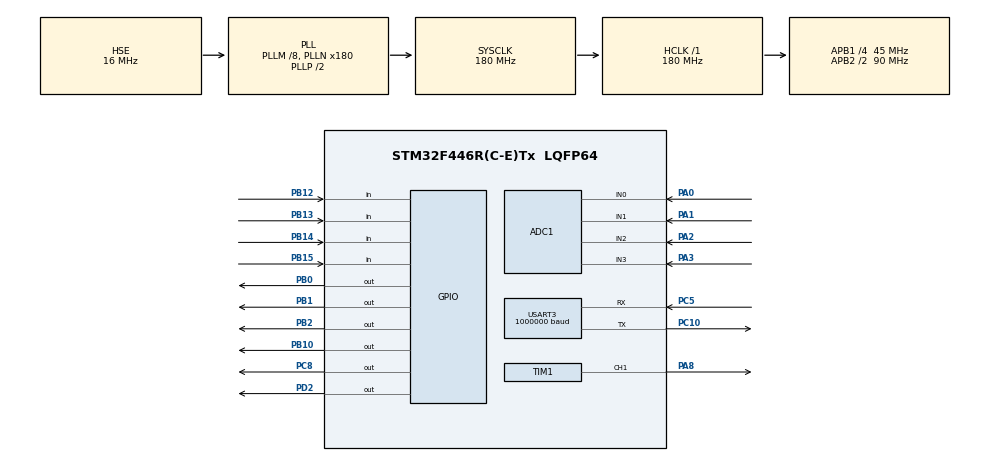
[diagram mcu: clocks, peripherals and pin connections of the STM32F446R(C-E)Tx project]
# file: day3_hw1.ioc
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ADC1.Channel-0\#ChannelRegularConversion=ADC_CHANNEL_0
ADC1.Channel-1\#ChannelRegularConversion=ADC_CHANNEL_1
ADC1.Channel-2\#ChannelRegularConversion=ADC_CHANNEL_2
ADC1.Channel-3\#ChannelRegularConversion=ADC_CHANNEL_3
ADC1.DMAContinuousRequests=ENABLE
ADC1.ExternalTrigConv=ADC_EXTERNALTRIGCONV_T8_TRGO
ADC1.NbrOfConversion=4
ADC1.NbrOfConversionFlag=1
ADC1.Rank-0\#ChannelRegularConversion=1
ADC1.Rank-1\#ChannelRegularConversion=2
ADC1.Rank-2\#ChannelRegularConversion=3
ADC1.Rank-3\#ChannelRegularConversion=4
ADC1.SamplingTime-0\#ChannelRegularConversion=ADC_SAMPLETIME_15CYCLES
ADC1.SamplingTime-1\#ChannelRegularConversion=ADC_SAMPLETIME_15CYCLES
ADC1.SamplingTime-2\#ChannelRegularConversion=ADC_SAMPLETIME_15CYCLES
ADC1.SamplingTime-3\#ChannelRegularConversion=ADC_SAMPLETIME_15CYCLES
ADC1.ScanConvMode=ENABLE
ADC1.master=1
Dma.ADC1.0.Direction=DMA_PERIPH_TO_MEMORY
Dma.ADC1.0.FIFOMode=DMA_FIFOMODE_DISABLE
Dma.ADC1.0.Instance=DMA2_Stream0
Dma.ADC1.0.MemDataAlignment=DMA_MDATAALIGN_WORD
Dma.ADC1.0.MemInc=DMA_MINC_ENABLE
Dma.ADC1.0.Mode=DMA_CIRCULAR
Dma.ADC1.0.PeriphDataAlignment=DMA_PDATAALIGN_WORD
Dma.ADC1.0.PeriphInc=DMA_PINC_DISABLE
Dma.ADC1.0.Priority=DMA_PRIORITY_LOW
Dma.Request0=ADC1
Dma.Request1=USART3_RX
Dma.USART3_RX.1.Direction=DMA_PERIPH_TO_MEMORY
Dma.USART3_RX.1.FIFOMode=DMA_FIFOMODE_DISABLE
Dma.USART3_RX.1.Instance=DMA1_Stream1
Dma.USART3_RX.1.MemDataAlignment=DMA_MDATAALIGN_BYTE
Dma.USART3_RX.1.MemInc=DMA_MINC_ENABLE
Dma.USART3_RX.1.Mode=DMA_CIRCULAR
Dma.USART3_RX.1.PeriphDataAlignment=DMA_PDATAALIGN_BYTE
Dma.USART3_RX.1.PeriphInc=DMA_PINC_DISABLE
Dma.USART3_RX.1.Priority=DMA_PRIORITY_LOW
Mcu.Family=STM32F4
Mcu.Name=STM32F446R(C-E)Tx
Mcu.Package=LQFP64
NVIC.ADC_IRQn=true\:0\:0\:false\:false\:true\:true\:true\:true
NVIC.DMA1_Stream1_IRQn=true\:0\:0\:false\:false\:true\:false\:true\:true
NVIC.DMA2_Stream0_IRQn=true\:0\:0\:false\:false\:true\:false\:true\:true
NVIC.PriorityGroup=NVIC_PRIORITYGROUP_4
NVIC.TIM1_BRK_TIM9_IRQn=true\:0\:0\:false\:false\:true\:true\:true\:true
NVIC.TIM1_CC_IRQn=true\:0\:0\:false\:false\:true\:true\:true\:true
NVIC.TIM1_TRG_COM_TIM11_IRQn=true\:0\:0\:false\:false\:true\:true\:true\:true
NVIC.TIM1_UP_TIM10_IRQn=true\:0\:0\:false\:false\:true\:true\:true\:true
NVIC.TIM6_DAC_IRQn=true\:0\:0\:false\:false\:true\:true\:true\:true
NVIC.TIM8_BRK_TIM12_IRQn=true\:0\:0\:false\:false\:true\:true\:true\:true
NVIC.TIM8_CC_IRQn=true\:0\:0\:false\:false\:true\:true\:true\:true
NVIC.TIM8_TRG_COM_TIM14_IRQn=true\:0\:0\:false\:false\:true\:true\:true\:true
NVIC.TIM8_UP_TIM13_IRQn=true\:0\:0\:false\:false\:true\:true\:true\:true
NVIC.USART3_IRQn=true\:0\:0\:false\:false\:true\:true\:true\:true
PA0-WKUP.Signal=ADCx_IN0
PA1.Signal=ADCx_IN1
PA13.Mode=Serial_Wire
PA13.Signal=SYS_JTMS-SWDIO
PA14.Mode=Serial_Wire
PA14.Signal=SYS_JTCK-SWCLK
PA2.Signal=ADCx_IN2
PA3.Signal=ADCx_IN3
PA8.Signal=S_TIM1_CH1
PB0.Signal=GPIO_Output
PB1.Signal=GPIO_Output
PB10.Signal=GPIO_Output
PB12.GPIO_PuPd=GPIO_PULLDOWN
PB12.Signal=GPIO_Input
PB13.GPIO_PuPd=GPIO_PULLDOWN
PB13.Signal=GPIO_Input
PB14.GPIO_PuPd=GPIO_PULLDOWN
PB14.Signal=GPIO_Input
PB15.GPIO_PuPd=GPIO_PULLDOWN
PB15.Signal=GPIO_Input
PB2.Signal=GPIO_Output
PC10.Mode=Asynchronous
PC10.Signal=USART3_TX
PC5.Mode=Asynchronous
PC5.Signal=USART3_RX
PC8.Signal=GPIO_Output
PD2.Signal=GPIO_Output
PH0-OSC_IN.Mode=HSE-External-Oscillator
PH0-OSC_IN.Signal=RCC_OSC_IN
PH1-OSC_OUT.Mode=HSE-External-Oscillator
PH1-OSC_OUT.Signal=RCC_OSC_OUT
ProjectManager.HeapSize=0x200
ProjectManager.StackSize=0x400
ProjectManager.TargetToolchain=STM32CubeIDE
RCC.AHBFreq_Value=180000000
RCC.APB1CLKDivider=RCC_HCLK_DIV4
RCC.APB1Freq_Value=45000000
RCC.APB1TimFreq_Value=90000000
RCC.APB2CLKDivider=RCC_HCLK_DIV2
RCC.APB2Freq_Value=90000000
RCC.APB2TimFreq_Value=180000000
RCC.CortexFreq_Value=180000000
RCC.HCLKFreq_Value=180000000
RCC.HSE_VALUE=16000000
RCC.PLLM=8
RCC.PLLN=180
RCC.PLLSourceVirtual=RCC_PLLSOURCE_HSE
RCC.SYSCLKFreq_VALUE=180000000
RCC.SYSCLKSource=RCC_SYSCLKSOURCE_PLLCLK
RCC.USBFreq_Value=180000000
RCC.VCOOutputFreq_Value=360000000
SH.ADCx_IN0.0=ADC1_IN0,IN0
SH.ADCx_IN1.0=ADC1_IN1,IN1
SH.ADCx_IN2.0=ADC1_IN2,IN2
SH.ADCx_IN3.0=ADC1_IN3,IN3
SH.S_TIM1_CH1.0=TIM1_CH1,PWM Generation1 CH1
TIM1.Channel-PWM\ Generation1\ CH1=TIM_CHANNEL_1
TIM1.Period=500-1
TIM1.Prescaler=18-1
TIM6.Period=100-1
TIM6.Prescaler=90-1
TIM8.Period=500-1
TIM8.Prescaler=18-1
USART3.BaudRate=1000000
USART3.VirtualMode=VM_ASYNC
VP_TIM6_VS_ClockSourceINT.Mode=Enable_Timer
board=custom

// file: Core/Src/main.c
/* USER CODE BEGIN Header */
/**
  ******************************************************************************
  * @file           : main.c
  * @brief          : Main program body
  ******************************************************************************
  * @attention
  *
  * Copyright (c) 2026 STMicroelectronics.
  * All rights reserved.
  *
  * This software is licensed under terms that can be found in the LICENSE file
  * in the root directory of this software component.
  * If no LICENSE file comes with this software, it is provided AS-IS.
  *
  ******************************************************************************
  */
/* USER CODE END Header */
#include "main.h"

ADC_HandleTypeDef hadc1;
DMA_HandleTypeDef hdma_adc1;

TIM_HandleTypeDef htim1;
TIM_HandleTypeDef htim6;
TIM_HandleTypeDef htim8;

void SystemClock_Config(void);
static void MX_GPIO_Init(void);
static void MX_DMA_Init(void);
static void MX_ADC1_Init(void);
static void MX_TIM1_Init(void);
static void MX_TIM8_Init(void);
static void MX_TIM6_Init(void);
static void MX_USART3_UART_Init(void);

int main(void)
{

  /* MCU Configuration--------------------------------------------------------*/

  /* Reset of all peripherals, Initializes the Flash interface and the Systick. */
  HAL_Init();

  /* Configure the system clock */
  SystemClock_Config();

  /* Initialize all configured peripherals */
  MX_GPIO_Init();
  MX_DMA_Init();
  MX_ADC1_Init();
  MX_TIM1_Init();
  MX_TIM8_Init();
  MX_TIM6_Init();
  MX_USART3_UART_Init();
  /* USER CODE BEGIN 2 */
  HAL_GPIO_WritePin(GPIOC, GPIO_PIN_8, GPIO_PIN_SET);  // Motor_Direction_R: 정방향 고정
  HAL_TIM_PWM_Start(&htim1, TIM_CHANNEL_1);
  TIM1->CCR1 = 0;   // 초기 상태: 정지

  /* USER CODE END 2 */

  /* Infinite loop */
  while (1)
  {

    /* USER CODE BEGIN 3 */
	  if(HAL_GPIO_ReadPin(GPIOB, GPIO_PIN_12) == GPIO_PIN_SET) {
	 	  TIM1->CCR1 = 0;
	  }
	  else if(HAL_GPIO_ReadPin(GPIOB, GPIO_PIN_13) == GPIO_PIN_SET) {
	 	  TIM1->CCR1 = 150;
	  }
	  else if(HAL_GPIO_ReadPin(GPIOB, GPIO_PIN_14) == GPIO_PIN_SET) {
	       TIM1->CCR1 = 250;
	  }
	  else if(HAL_GPIO_ReadPin(GPIOB, GPIO_PIN_15) == GPIO_PIN_SET) {
	   	  TIM1->CCR1 = 350;
	  }
	  else {
		  TIM1->CCR1 = 0;   // 아무 스위치도 안 올렸을 때 정지
	  }
  }
  /* USER CODE END 3 */
}

void SystemClock_Config(void)
{
  RCC_OscInitTypeDef RCC_OscInitStruct = {0};
  RCC_ClkInitTypeDef RCC_ClkInitStruct = {0};

  /** Configure the main internal regulator output voltage
  */
  __HAL_RCC_PWR_CLK_ENABLE();
  __HAL_PWR_VOLTAGESCALING_CONFIG(PWR_REGULATOR_VOLTAGE_SCALE1);

  /** Initializes the RCC Oscillators according to the specified parameters
  * in the RCC_OscInitTypeDef structure.
  */
  RCC_OscInitStruct.OscillatorType = RCC_OSCILLATORTYPE_HSE;
  RCC_OscInitStruct.HSEState = RCC_HSE_ON;
  RCC_OscInitStruct.PLL.PLLState = RCC_PLL_ON;
  RCC_OscInitStruct.PLL.PLLSource = RCC_PLLSOURCE_HSE;
  RCC_OscInitStruct.PLL.PLLM = 8;
  RCC_OscInitStruct.PLL.PLLN = 180;
  RCC_OscInitStruct.PLL.PLLP = RCC_PLLP_DIV2;
  RCC_OscInitStruct.PLL.PLLQ = 2;
  RCC_OscInitStruct.PLL.PLLR = 2;
  if (HAL_RCC_OscConfig(&RCC_OscInitStruct) != HAL_OK)
  {
    Error_Handler();
  }

  /** Activate the Over-Drive mode
  */
  if (HAL_PWREx_EnableOverDrive() != HAL_OK)
  {
    Error_Handler();
  }

  /** Initializes the CPU, AHB and APB buses clocks
  */
  RCC_ClkInitStruct.ClockType = RCC_CLOCKTYPE_HCLK|RCC_CLOCKTYPE_SYSCLK
                              |RCC_CLOCKTYPE_PCLK1|RCC_CLOCKTYPE_PCLK2;
  RCC_ClkInitStruct.SYSCLKSource = RCC_SYSCLKSOURCE_PLLCLK;
  RCC_ClkInitStruct.AHBCLKDivider = RCC_SYSCLK_DIV1;
  RCC_ClkInitStruct.APB1CLKDivider = RCC_HCLK_DIV4;
  RCC_ClkInitStruct.APB2CLKDivider = RCC_HCLK_DIV2;

  if (HAL_RCC_ClockConfig(&RCC_ClkInitStruct, FLASH_LATENCY_5) != HAL_OK)
  {
    Error_Handler();
  }
}

static void MX_ADC1_Init(void)
{

  ADC_ChannelConfTypeDef sConfig = {0};

  /** Configure the global features of the ADC (Clock, Resolution, Data Alignment and number of conversion)
  */
  hadc1.Instance = ADC1;
  hadc1.Init.ClockPrescaler = ADC_CLOCK_SYNC_PCLK_DIV4;
  hadc1.Init.Resolution = ADC_RESOLUTION_12B;
  hadc1.Init.ScanConvMode = ENABLE;
  hadc1.Init.ContinuousConvMode = DISABLE;
  hadc1.Init.DiscontinuousConvMode = DISABLE;
  hadc1.Init.ExternalTrigConvEdge = ADC_EXTERNALTRIGCONVEDGE_RISING;
  hadc1.Init.ExternalTrigConv = ADC_EXTERNALTRIGCONV_T8_TRGO;
  hadc1.Init.DataAlign = ADC_DATAALIGN_RIGHT;
  hadc1.Init.NbrOfConversion = 4;
  hadc1.Init.DMAContinuousRequests = ENABLE;
  hadc1.Init.EOCSelection = ADC_EOC_SINGLE_CONV;
  if (HAL_ADC_Init(&hadc1) != HAL_OK)
  {
    Error_Handler();
  }

  /** Configure for the selected ADC regular channel its corresponding rank in the sequencer and its sample time.
  */
  sConfig.Channel = ADC_CHANNEL_0;
  sConfig.Rank = 1;
  sConfig.SamplingTime = ADC_SAMPLETIME_15CYCLES;
  if (HAL_ADC_ConfigChannel(&hadc1, &sConfig) != HAL_OK)
  {
    Error_Handler();
  }

  /** Configure for the selected ADC regular channel its corresponding rank in the sequencer and its sample time.
  */
  sConfig.Channel = ADC_CHANNEL_1;
  sConfig.Rank = 2;
  if (HAL_ADC_ConfigChannel(&hadc1, &sConfig) != HAL_OK)
  {
    Error_Handler();
  }

  /** Configure for the selected ADC regular channel its corresponding rank in the sequencer and its sample time.
  */
  sConfig.Channel = ADC_CHANNEL_2;
  sConfig.Rank = 3;
  if (HAL_ADC_ConfigChannel(&hadc1, &sConfig) != HAL_OK)
  {
    Error_Handler();
  }

  /** Configure for the selected ADC regular channel its corresponding rank in the sequencer and its sample time.
  */
  sConfig.Channel = ADC_CHANNEL_3;
  sConfig.Rank = 4;
  if (HAL_ADC_ConfigChannel(&hadc1, &sConfig) != HAL_OK)
  {
    Error_Handler();
  }

}

static void MX_TIM6_Init(void)
{

  TIM_MasterConfigTypeDef sMasterConfig = {0};

  htim6.Instance = TIM6;
  htim6.Init.Prescaler = 90-1;
  htim6.Init.CounterMode = TIM_COUNTERMODE_UP;
  htim6.Init.Period = 100-1;
  htim6.Init.AutoReloadPreload = TIM_AUTORELOAD_PRELOAD_DISABLE;
  if (HAL_TIM_Base_Init(&htim6) != HAL_OK)
  {
    Error_Handler();
  }
  sMasterConfig.MasterOutputTrigger = TIM_TRGO_RESET;
  sMasterConfig.MasterSlaveMode = TIM_MASTERSLAVEMODE_DISABLE;
  if (HAL_TIMEx_MasterConfigSynchronization(&htim6, &sMasterConfig) != HAL_OK)
  {
    Error_Handler();
  }

}

static void MX_TIM1_Init(void)
{

  TIM_MasterConfigTypeDef sMasterConfig = {0};
  TIM_OC_InitTypeDef sConfigOC = {0};
  TIM_BreakDeadTimeConfigTypeDef sBreakDeadTimeConfig = {0};

  htim1.Instance = TIM1;
  htim1.Init.Prescaler = 18-1;
  htim1.Init.CounterMode = TIM_COUNTERMODE_UP;
  htim1.Init.Period = 500-1;
  htim1.Init.ClockDivision = TIM_CLOCKDIVISION_DIV1;
  htim1.Init.RepetitionCounter = 0;
  htim1.Init.AutoReloadPreload = TIM_AUTORELOAD_PRELOAD_DISABLE;
  if (HAL_TIM_PWM_Init(&htim1) != HAL_OK)
  {
    Error_Handler();
  }
  sMasterConfig.MasterOutputTrigger = TIM_TRGO_RESET;
  sMasterConfig.MasterSlaveMode = TIM_MASTERSLAVEMODE_DISABLE;
  if (HAL_TIMEx_MasterConfigSynchronization(&htim1, &sMasterConfig) != HAL_OK)
  {
    Error_Handler();
  }
  sConfigOC.OCMode = TIM_OCMODE_PWM1;
  sConfigOC.Pulse = 0;
  sConfigOC.OCPolarity = TIM_OCPOLARITY_HIGH;
  sConfigOC.OCNPolarity = TIM_OCNPOLARITY_HIGH;
  sConfigOC.OCFastMode = TIM_OCFAST_DISABLE;
  sConfigOC.OCIdleState = TIM_OCIDLESTATE_RESET;
  sConfigOC.OCNIdleState = TIM_OCNIDLESTATE_RESET;
  if (HAL_TIM_PWM_ConfigChannel(&htim1, &sConfigOC, TIM_CHANNEL_1) != HAL_OK)
  {
    Error_Handler();
  }
  sBreakDeadTimeConfig.OffStateRunMode = TIM_OSSR_DISABLE;
  sBreakDeadTimeConfig.OffStateIDLEMode = TIM_OSSI_DISABLE;
  sBreakDeadTimeConfig.LockLevel = TIM_LOCKLEVEL_OFF;
  sBreakDeadTimeConfig.DeadTime = 0;
  sBreakDeadTimeConfig.BreakState = TIM_BREAK_DISABLE;
  sBreakDeadTimeConfig.BreakPolarity = TIM_BREAKPOLARITY_HIGH;
  sBreakDeadTimeConfig.AutomaticOutput = TIM_AUTOMATICOUTPUT_DISABLE;
  if (HAL_TIMEx_ConfigBreakDeadTime(&htim1, &sBreakDeadTimeConfig) != HAL_OK)
  {
    Error_Handler();
  }
  HAL_TIM_MspPostInit(&htim1);

}

static void MX_TIM8_Init(void)
{

  TIM_MasterConfigTypeDef sMasterConfig = {0};

  htim8.Instance = TIM8;
  htim8.Init.Prescaler = 18-1;
  htim8.Init.CounterMode = TIM_COUNTERMODE_UP;
  htim8.Init.Period = 500-1;
  htim8.Init.ClockDivision = TIM_CLOCKDIVISION_DIV1;
  htim8.Init.RepetitionCounter = 0;
  htim8.Init.AutoReloadPreload = TIM_AUTORELOAD_PRELOAD_DISABLE;
  if (HAL_TIM_Base_Init(&htim8) != HAL_OK)
  {
    Error_Handler();
  }
  sMasterConfig.MasterOutputTrigger = TIM_TRGO_RESET;
  sMasterConfig.MasterSlaveMode = TIM_MASTERSLAVEMODE_DISABLE;
  if (HAL_TIMEx_MasterConfigSynchronization(&htim8, &sMasterConfig) != HAL_OK)
  {
    Error_Handler();
  }

}

static void MX_USART3_UART_Init(void)
{

  LL_USART_InitTypeDef USART_InitStruct = {0};

  LL_GPIO_InitTypeDef GPIO_InitStruct = {0};

  /* Peripheral clock enable */
  LL_APB1_GRP1_EnableClock(LL_APB1_GRP1_PERIPH_USART3);

  LL_AHB1_GRP1_EnableClock(LL_AHB1_GRP1_PERIPH_GPIOC);
  /**USART3 GPIO Configuration
  PC5   ------> USART3_RX
  PC10   ------> USART3_TX
  */
  GPIO_InitStruct.Pin = LL_GPIO_PIN_5|LL_GPIO_PIN_10;
  GPIO_InitStruct.Mode = LL_GPIO_MODE_ALTERNATE;
  GPIO_InitStruct.Speed = LL_GPIO_SPEED_FREQ_VERY_HIGH;
  GPIO_InitStruct.OutputType = LL_GPIO_OUTPUT_PUSHPULL;
  GPIO_InitStruct.Pull = LL_GPIO_PULL_NO;
  GPIO_InitStruct.Alternate = LL_GPIO_AF_7;
  LL_GPIO_Init(GPIOC, &GPIO_InitStruct);

  /* USART3 DMA Init */

  /* USART3_RX Init */
  LL_DMA_SetChannelSelection(DMA1, LL_DMA_STREAM_1, LL_DMA_CHANNEL_4);

  LL_DMA_SetDataTransferDirection(DMA1, LL_DMA_STREAM_1, LL_DMA_DIRECTION_PERIPH_TO_MEMORY);

  LL_DMA_SetStreamPriorityLevel(DMA1, LL_DMA_STREAM_1, LL_DMA_PRIORITY_LOW);

  LL_DMA_SetMode(DMA1, LL_DMA_STREAM_1, LL_DMA_MODE_CIRCULAR);

  LL_DMA_SetPeriphIncMode(DMA1, LL_DMA_STREAM_1, LL_DMA_PERIPH_NOINCREMENT);

  LL_DMA_SetMemoryIncMode(DMA1, LL_DMA_STREAM_1, LL_DMA_MEMORY_INCREMENT);

  LL_DMA_SetPeriphSize(DMA1, LL_DMA_STREAM_1, LL_DMA_PDATAALIGN_BYTE);

  LL_DMA_SetMemorySize(DMA1, LL_DMA_STREAM_1, LL_DMA_MDATAALIGN_BYTE);

  LL_DMA_DisableFifoMode(DMA1, LL_DMA_STREAM_1);

  /* USART3 interrupt Init */
  NVIC_SetPriority(USART3_IRQn, NVIC_EncodePriority(NVIC_GetPriorityGrouping(),0, 0));
  NVIC_EnableIRQ(USART3_IRQn);

  USART_InitStruct.BaudRate = 1000000;
  USART_InitStruct.DataWidth = LL_USART_DATAWIDTH_8B;
  USART_InitStruct.StopBits = LL_USART_STOPBITS_1;
  USART_InitStruct.Parity = LL_USART_PARITY_NONE;
  USART_InitStruct.TransferDirection = LL_USART_DIRECTION_TX_RX;
  USART_InitStruct.HardwareFlowControl = LL_USART_HWCONTROL_NONE;
  USART_InitStruct.OverSampling = LL_USART_OVERSAMPLING_16;
  LL_USART_Init(USART3, &USART_InitStruct);
  LL_USART_ConfigAsyncMode(USART3);
  LL_USART_Enable(USART3);

}

static void MX_DMA_Init(void)
{

  /* DMA controller clock enable */
  __HAL_RCC_DMA2_CLK_ENABLE();
  __HAL_RCC_DMA1_CLK_ENABLE();

  /* DMA interrupt init */
  /* DMA1_Stream1_IRQn interrupt configuration */
  NVIC_SetPriority(DMA1_Stream1_IRQn, NVIC_EncodePriority(NVIC_GetPriorityGrouping(),0, 0));
  NVIC_EnableIRQ(DMA1_Stream1_IRQn);
  /* DMA2_Stream0_IRQn interrupt configuration */
  HAL_NVIC_SetPriority(DMA2_Stream0_IRQn, 0, 0);
  HAL_NVIC_EnableIRQ(DMA2_Stream0_IRQn);

}

static void MX_GPIO_Init(void)
{
  GPIO_InitTypeDef GPIO_InitStruct = {0};

  /* GPIO Ports Clock Enable */
  __HAL_RCC_GPIOH_CLK_ENABLE();
  __HAL_RCC_GPIOA_CLK_ENABLE();
  __HAL_RCC_GPIOC_CLK_ENABLE();
  __HAL_RCC_GPIOB_CLK_ENABLE();
  __HAL_RCC_GPIOD_CLK_ENABLE();

  /*Configure GPIO pin Output Level */
  HAL_GPIO_WritePin(GPIOB, GPIO_PIN_0|GPIO_PIN_1|GPIO_PIN_2|GPIO_PIN_10, GPIO_PIN_RESET);

  /*Configure GPIO pin Output Level */
  HAL_GPIO_WritePin(GPIOC, GPIO_PIN_8, GPIO_PIN_RESET);

  /*Configure GPIO pin Output Level */
  HAL_GPIO_WritePin(GPIOD, GPIO_PIN_2, GPIO_PIN_RESET);

  /*Configure GPIO pins : PB0 PB1 PB2 PB10 */
  GPIO_InitStruct.Pin = GPIO_PIN_0|GPIO_PIN_1|GPIO_PIN_2|GPIO_PIN_10;
  GPIO_InitStruct.Mode = GPIO_MODE_OUTPUT_PP;
  GPIO_InitStruct.Pull = GPIO_NOPULL;
  GPIO_InitStruct.Speed = GPIO_SPEED_FREQ_LOW;
  HAL_GPIO_Init(GPIOB, &GPIO_InitStruct);

  /*Configure GPIO pins : PB12 PB13 PB14 PB15 */
  GPIO_InitStruct.Pin = GPIO_PIN_12|GPIO_PIN_13|GPIO_PIN_14|GPIO_PIN_15;
  GPIO_InitStruct.Mode = GPIO_MODE_INPUT;
  GPIO_InitStruct.Pull = GPIO_PULLDOWN;
  HAL_GPIO_Init(GPIOB, &GPIO_InitStruct);

  /*Configure GPIO pin : PC8 */
  GPIO_InitStruct.Pin = GPIO_PIN_8;
  GPIO_InitStruct.Mode = GPIO_MODE_OUTPUT_PP;
  GPIO_InitStruct.Pull = GPIO_NOPULL;
  GPIO_InitStruct.Speed = GPIO_SPEED_FREQ_LOW;
  HAL_GPIO_Init(GPIOC, &GPIO_InitStruct);

  /*Configure GPIO pin : PD2 */
  GPIO_InitStruct.Pin = GPIO_PIN_2;
  GPIO_InitStruct.Mode = GPIO_MODE_OUTPUT_PP;
  GPIO_InitStruct.Pull = GPIO_NOPULL;
  GPIO_InitStruct.Speed = GPIO_SPEED_FREQ_LOW;
  HAL_GPIO_Init(GPIOD, &GPIO_InitStruct);

}

void Error_Handler(void)
{
  __disable_irq();
  while (1)
  {
  }
}
